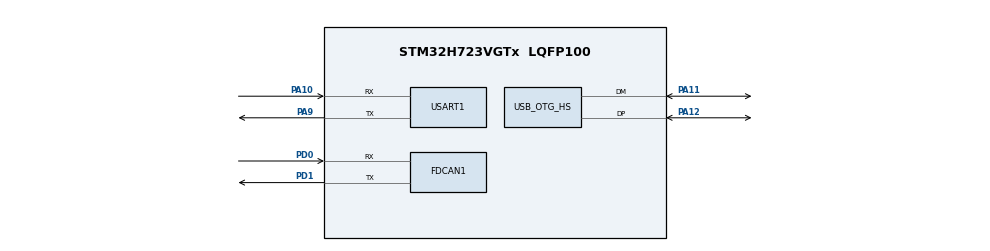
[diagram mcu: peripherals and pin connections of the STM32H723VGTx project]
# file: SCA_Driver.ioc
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CORTEX_M7.default_mode_Activation=1
Dma.Request0=USART1_RX
Dma.USART1_RX.0.Direction=DMA_PERIPH_TO_MEMORY
Dma.USART1_RX.0.EventEnable=DISABLE
Dma.USART1_RX.0.FIFOMode=DMA_FIFOMODE_DISABLE
Dma.USART1_RX.0.Instance=DMA1_Stream0
Dma.USART1_RX.0.MemDataAlignment=DMA_MDATAALIGN_BYTE
Dma.USART1_RX.0.MemInc=DMA_MINC_ENABLE
Dma.USART1_RX.0.Mode=DMA_NORMAL
Dma.USART1_RX.0.PeriphDataAlignment=DMA_PDATAALIGN_BYTE
Dma.USART1_RX.0.PeriphInc=DMA_PINC_DISABLE
Dma.USART1_RX.0.Polarity=HAL_DMAMUX_REQ_GEN_RISING
Dma.USART1_RX.0.Priority=DMA_PRIORITY_LOW
Dma.USART1_RX.0.RequestNumber=1
Dma.USART1_RX.0.SignalID=NONE
Dma.USART1_RX.0.SyncEnable=DISABLE
Dma.USART1_RX.0.SyncPolarity=HAL_DMAMUX_SYNC_NO_EVENT
Dma.USART1_RX.0.SyncRequestNumber=1
Dma.USART1_RX.0.SyncSignalID=NONE
FDCAN1.CalculateBaudRateNominal=1000000
FDCAN1.CalculateTimeBitNominal=1000
FDCAN1.CalculateTimeQuantumNominal=166.66666666666666
FDCAN1.NominalPrescaler=4
FDCAN1.NominalTimeSeg2=3
FDCAN1.RxFifo0ElmtsNbr=16
FDCAN1.RxFifo1ElmtsNbr=16
FDCAN1.TxFifoQueueElmtsNbr=16
FREERTOS.Tasks01=defaultTask,0,128,StartDefaultTask,Default,NULL,Dynamic,NULL,NULL
FREERTOS.configMAX_PRIORITIES=10
FREERTOS.configTIMER_TASK_PRIORITY=8
FREERTOS.configTOTAL_HEAP_SIZE=32768
FREERTOS.configUSE_STATS_FORMATTING_FUNCTIONS=1
FREERTOS.configUSE_TIMERS=1
FREERTOS.configUSE_TRACE_FACILITY=1
Mcu.Family=STM32H7
Mcu.Name=STM32H723VGTx
Mcu.Package=LQFP100
NVIC.DMA1_Stream0_IRQn=true\:5\:0\:false\:false\:true\:true\:false\:true\:true
NVIC.FDCAN1_IT0_IRQn=true\:5\:0\:false\:false\:true\:true\:true\:true\:true
NVIC.FDCAN1_IT1_IRQn=true\:5\:0\:false\:false\:true\:true\:true\:true\:true
NVIC.OTG_HS_IRQn=true\:5\:0\:false\:false\:true\:true\:false\:true\:true
NVIC.PriorityGroup=NVIC_PRIORITYGROUP_4
NVIC.TIM17_IRQn=true\:15\:0\:false\:false\:true\:false\:false\:true\:true
NVIC.TimeBase=TIM17_IRQn
NVIC.TimeBaseIP=TIM17
NVIC.USART1_IRQn=true\:5\:0\:false\:false\:true\:true\:true\:true\:true
PA10.Mode=Asynchronous
PA10.Signal=USART1_RX
PA11.Mode=Device_Only_FS
PA11.Signal=USB_OTG_HS_DM
PA12.Mode=Device_Only_FS
PA12.Signal=USB_OTG_HS_DP
PA9.Mode=Asynchronous
PA9.Signal=USART1_TX
PD0.Mode=FDCAN_Activate
PD0.Signal=FDCAN1_RX
PD1.Mode=FDCAN_Activate
PD1.Signal=FDCAN1_TX
PH0-OSC_IN.Mode=HSE-External-Oscillator
PH0-OSC_IN.Signal=RCC_OSC_IN
PH1-OSC_OUT.Mode=HSE-External-Oscillator
PH1-OSC_OUT.Signal=RCC_OSC_OUT
ProjectManager.HeapSize=0x200
ProjectManager.StackSize=0x400
ProjectManager.TargetToolchain=MDK-ARM V5.32
RCC.ADCFreq_Value=48375000
RCC.APB1Freq_Value=137500000
RCC.APB2Freq_Value=137500000
RCC.APB3Freq_Value=137500000
RCC.APB4Freq_Value=137500000
RCC.CortexFreq_Value=550000000
RCC.D1PPRE=RCC_APB3_DIV2
RCC.D2PPRE1=RCC_APB1_DIV2
RCC.D2PPRE2=RCC_APB2_DIV2
RCC.D3PPRE=RCC_APB4_DIV2
RCC.DIVM1=3
RCC.DIVN1=68
RCC.DIVP1=1
RCC.FDCANCLockSelection=RCC_FDCANCLKSOURCE_HSE
RCC.HCLKFreq_Value=275000000
RCC.HPRE=RCC_HCLK_DIV2
RCC.HSE_VALUE=24000000
RCC.PLLFRACN=6144
RCC.PLLSourceVirtual=RCC_PLLSOURCE_HSE
RCC.SYSCLKFreq_VALUE=550000000
RCC.SYSCLKSource=RCC_SYSCLKSOURCE_PLLCLK
RCC.USBCLockSelection=RCC_USBCLKSOURCE_HSI48
RCC.USBFreq_Value=48000000
USART1.VirtualMode-Asynchronous=VM_ASYNC
USB_DEVICE.CLASS_NAME_HS=CDC
USB_DEVICE.VirtualMode=Cdc
USB_DEVICE.VirtualModeHS=Cdc_HS
USB_OTG_HS.VirtualMode-Device_Only_FS=Device_Only_FS
VP_FREERTOS_VS_CMSIS_V1.Mode=CMSIS_V1
VP_SYS_VS_tim17.Mode=TIM17
VP_USB_DEVICE_VS_USB_DEVICE_CDC_HS.Mode=CDC_HS
board=custom

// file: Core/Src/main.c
/* USER CODE BEGIN Header */
/**
  ******************************************************************************
  * @file           : main.c
  * @brief          : Main program body
  ******************************************************************************
  * @attention
  *
  * Copyright (c) 2024 STMicroelectronics.
  * All rights reserved.
  *
  * This software is licensed under terms that can be found in the LICENSE file
  * in the root directory of this software component.
  * If no LICENSE file comes with this software, it is provided AS-IS.
  *
  ******************************************************************************
  */
/* USER CODE END Header */
#include "main.h"
#include "cmsis_os.h"
#include "dma.h"
#include "fdcan.h"
#include "usart.h"
#include "usb_device.h"
#include "gpio.h"

/* USER CODE BEGIN Includes */
#include "system.h"
#include "global.h"
/* USER CODE END Includes */

void SystemClock_Config(void);
static void MPU_Config(void);
void MX_FREERTOS_Init(void);

int main(void)
{

  /* MPU Configuration--------------------------------------------------------*/
  MPU_Config();

  /* MCU Configuration--------------------------------------------------------*/

  /* Reset of all peripherals, Initializes the Flash interface and the Systick. */
  HAL_Init();

  /* Configure the system clock */
  SystemClock_Config();

  /* Initialize all configured peripherals */
  MX_GPIO_Init();
  MX_DMA_Init();
  MX_FDCAN1_Init();
  MX_USART1_UART_Init();
  /* USER CODE BEGIN 2 */
	debug_init();
	start_task_init();
  /* USER CODE END 2 */

  /* Call init function for freertos objects (in cmsis_os2.c) */
  MX_FREERTOS_Init();

  /* Start scheduler */
  osKernelStart();

  /* We should never get here as control is now taken by the scheduler */

  /* Infinite loop */
  while (1)
  {

  }
}

void SystemClock_Config(void)
{
  RCC_OscInitTypeDef RCC_OscInitStruct = {0};
  RCC_ClkInitTypeDef RCC_ClkInitStruct = {0};

  /** Supply configuration update enable
  */
  HAL_PWREx_ConfigSupply(PWR_LDO_SUPPLY);

  /** Configure the main internal regulator output voltage
  */
  __HAL_PWR_VOLTAGESCALING_CONFIG(PWR_REGULATOR_VOLTAGE_SCALE0);

  while(!__HAL_PWR_GET_FLAG(PWR_FLAG_VOSRDY)) {}

  /** Initializes the RCC Oscillators according to the specified parameters
  * in the RCC_OscInitTypeDef structure.
  */
  RCC_OscInitStruct.OscillatorType = RCC_OSCILLATORTYPE_HSI48|RCC_OSCILLATORTYPE_HSE;
  RCC_OscInitStruct.HSEState = RCC_HSE_ON;
  RCC_OscInitStruct.HSI48State = RCC_HSI48_ON;
  RCC_OscInitStruct.PLL.PLLState = RCC_PLL_ON;
  RCC_OscInitStruct.PLL.PLLSource = RCC_PLLSOURCE_HSE;
  RCC_OscInitStruct.PLL.PLLM = 3;
  RCC_OscInitStruct.PLL.PLLN = 68;
  RCC_OscInitStruct.PLL.PLLP = 1;
  RCC_OscInitStruct.PLL.PLLQ = 2;
  RCC_OscInitStruct.PLL.PLLR = 2;
  RCC_OscInitStruct.PLL.PLLRGE = RCC_PLL1VCIRANGE_3;
  RCC_OscInitStruct.PLL.PLLVCOSEL = RCC_PLL1VCOWIDE;
  RCC_OscInitStruct.PLL.PLLFRACN = 6144;
  if (HAL_RCC_OscConfig(&RCC_OscInitStruct) != HAL_OK)
  {
    Error_Handler();
  }

  /** Initializes the CPU, AHB and APB buses clocks
  */
  RCC_ClkInitStruct.ClockType = RCC_CLOCKTYPE_HCLK|RCC_CLOCKTYPE_SYSCLK
                              |RCC_CLOCKTYPE_PCLK1|RCC_CLOCKTYPE_PCLK2
                              |RCC_CLOCKTYPE_D3PCLK1|RCC_CLOCKTYPE_D1PCLK1;
  RCC_ClkInitStruct.SYSCLKSource = RCC_SYSCLKSOURCE_PLLCLK;
  RCC_ClkInitStruct.SYSCLKDivider = RCC_SYSCLK_DIV1;
  RCC_ClkInitStruct.AHBCLKDivider = RCC_HCLK_DIV2;
  RCC_ClkInitStruct.APB3CLKDivider = RCC_APB3_DIV2;
  RCC_ClkInitStruct.APB1CLKDivider = RCC_APB1_DIV2;
  RCC_ClkInitStruct.APB2CLKDivider = RCC_APB2_DIV2;
  RCC_ClkInitStruct.APB4CLKDivider = RCC_APB4_DIV2;

  if (HAL_RCC_ClockConfig(&RCC_ClkInitStruct, FLASH_LATENCY_3) != HAL_OK)
  {
    Error_Handler();
  }
}

 /* MPU Configuration */

void MPU_Config(void)
{
  MPU_Region_InitTypeDef MPU_InitStruct = {0};

  /* Disables the MPU */
  HAL_MPU_Disable();

  /** Initializes and configures the Region and the memory to be protected
  */
  MPU_InitStruct.Enable = MPU_REGION_ENABLE;
  MPU_InitStruct.Number = MPU_REGION_NUMBER0;
  MPU_InitStruct.BaseAddress = 0x0;
  MPU_InitStruct.Size = MPU_REGION_SIZE_4GB;
  MPU_InitStruct.SubRegionDisable = 0x87;
  MPU_InitStruct.TypeExtField = MPU_TEX_LEVEL0;
  MPU_InitStruct.AccessPermission = MPU_REGION_NO_ACCESS;
  MPU_InitStruct.DisableExec = MPU_INSTRUCTION_ACCESS_DISABLE;
  MPU_InitStruct.IsShareable = MPU_ACCESS_SHAREABLE;
  MPU_InitStruct.IsCacheable = MPU_ACCESS_NOT_CACHEABLE;
  MPU_InitStruct.IsBufferable = MPU_ACCESS_NOT_BUFFERABLE;

  HAL_MPU_ConfigRegion(&MPU_InitStruct);
  /* Enables the MPU */
  HAL_MPU_Enable(MPU_PRIVILEGED_DEFAULT);

}

void HAL_TIM_PeriodElapsedCallback(TIM_HandleTypeDef *htim)
{
  if (htim->Instance == TIM17) {
    HAL_IncTick();
    rtc_ms++;
  }
}

void Error_Handler(void)
{
  __disable_irq();
  while (1)
  {
  }
}

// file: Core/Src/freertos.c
/* USER CODE BEGIN Header */
/**
  ******************************************************************************
  * File Name          : freertos.c
  * Description        : Code for freertos applications
  ******************************************************************************
  * @attention
  *
  * Copyright (c) 2024 STMicroelectronics.
  * All rights reserved.
  *
  * This software is licensed under terms that can be found in the LICENSE file
  * in the root directory of this software component.
  * If no LICENSE file comes with this software, it is provided AS-IS.
  *
  ******************************************************************************
  */
/* USER CODE END Header */

#include "FreeRTOS.h"
#include "task.h"
#include "main.h"
#include "cmsis_os.h"

osThreadId defaultTaskHandle;

void StartDefaultTask(void const * argument);

extern void MX_USB_DEVICE_Init(void);
void MX_FREERTOS_Init(void); /* (MISRA C 2004 rule 8.1) */

/* GetIdleTaskMemory prototype (linked to static allocation support) */
void vApplicationGetIdleTaskMemory( StaticTask_t **ppxIdleTaskTCBBuffer, StackType_t **ppxIdleTaskStackBuffer, uint32_t *pulIdleTaskStackSize );

/* GetTimerTaskMemory prototype (linked to static allocation support) */
void vApplicationGetTimerTaskMemory( StaticTask_t **ppxTimerTaskTCBBuffer, StackType_t **ppxTimerTaskStackBuffer, uint32_t *pulTimerTaskStackSize );

/* USER CODE BEGIN GET_IDLE_TASK_MEMORY */
static StaticTask_t xIdleTaskTCBBuffer;
static StackType_t xIdleStack[configMINIMAL_STACK_SIZE];

void vApplicationGetIdleTaskMemory( StaticTask_t **ppxIdleTaskTCBBuffer, StackType_t **ppxIdleTaskStackBuffer, uint32_t *pulIdleTaskStackSize )
{
  *ppxIdleTaskTCBBuffer = &xIdleTaskTCBBuffer;
  *ppxIdleTaskStackBuffer = &xIdleStack[0];
  *pulIdleTaskStackSize = configMINIMAL_STACK_SIZE;
  /* place for user code */
}
/* USER CODE END GET_IDLE_TASK_MEMORY */

/* USER CODE BEGIN GET_TIMER_TASK_MEMORY */
static StaticTask_t xTimerTaskTCBBuffer;
static StackType_t xTimerStack[configTIMER_TASK_STACK_DEPTH];

void vApplicationGetTimerTaskMemory( StaticTask_t **ppxTimerTaskTCBBuffer, StackType_t **ppxTimerTaskStackBuffer, uint32_t *pulTimerTaskStackSize )
{
  *ppxTimerTaskTCBBuffer = &xTimerTaskTCBBuffer;
  *ppxTimerTaskStackBuffer = &xTimerStack[0];
  *pulTimerTaskStackSize = configTIMER_TASK_STACK_DEPTH;
  /* place for user code */
}
/* USER CODE END GET_TIMER_TASK_MEMORY */

void MX_FREERTOS_Init(void) {

  /* Create the thread(s) */
  /* definition and creation of defaultTask */
  osThreadDef(defaultTask, StartDefaultTask, osPriorityNormal, 0, 128);
  defaultTaskHandle = osThreadCreate(osThread(defaultTask), NULL);

}

void StartDefaultTask(void const * argument)
{
  /* init code for USB_DEVICE */
  MX_USB_DEVICE_Init();
  for(;;)
  {
    osDelay(1);
  }
}
